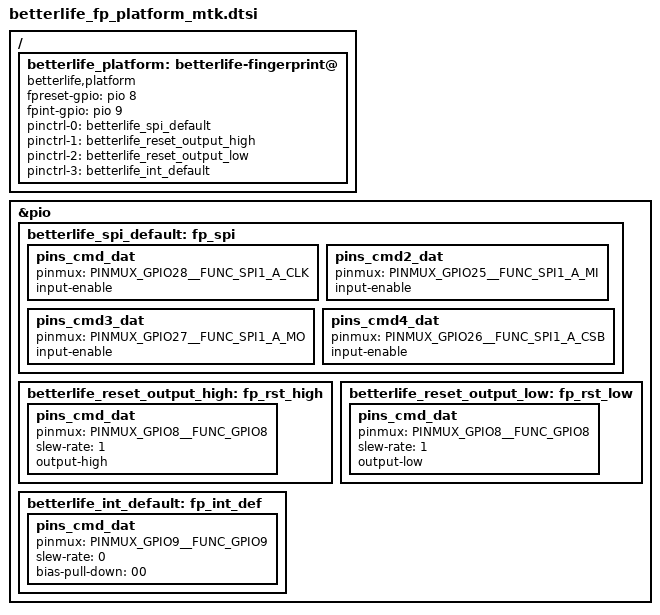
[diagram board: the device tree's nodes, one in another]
//blestech add
/{
betterlife_platform: betterlife-fingerprint@ {
	compatible = "betterlife,platform";
	fpreset-gpio = <&pio 8 0>;
	fpint-gpio = <&pio 9 0>;
	status = "okay";
	};
};

&pio{
	betterlife_spi_default:fp_spi{

		pins_cmd_dat {
			pinmux = <PINMUX_GPIO28__FUNC_SPI1_A_CLK>;
			input-enable;
		};
		pins_cmd2_dat {
			pinmux = <PINMUX_GPIO25__FUNC_SPI1_A_MI>;
			input-enable;
		};
		pins_cmd3_dat {
			pinmux = <PINMUX_GPIO27__FUNC_SPI1_A_MO>;
			input-enable;
		};
		pins_cmd4_dat {
			pinmux = <PINMUX_GPIO26__FUNC_SPI1_A_CSB>;
			input-enable;
		};
	};
	betterlife_reset_output_high:fp_rst_high{
		pins_cmd_dat {
			pinmux = <PINMUX_GPIO8__FUNC_GPIO8>;
			slew-rate = <1>;
			output-high;
		};
	};
	betterlife_reset_output_low:fp_rst_low{
		pins_cmd_dat {
			pinmux = <PINMUX_GPIO8__FUNC_GPIO8>;
			slew-rate = <1>;
			output-low;
		};
	};


	betterlife_int_default:fp_int_def{
		pins_cmd_dat {			
			pinmux = <PINMUX_GPIO9__FUNC_GPIO9>;
			slew-rate = <0>;
			bias-pull-down = <00>;
		};
	};
};

&betterlife_platform{
	pinctrl-names = "spi_default", "reset-output-high", "reset-output-low", "int_default";
	pinctrl-0 = <&betterlife_spi_default>;
	pinctrl-1 = <&betterlife_reset_output_high>;
	pinctrl-2 = <&betterlife_reset_output_low>;
	pinctrl-3 = <&betterlife_int_default>;
	status = "okay";
};
//blestech end
